# SG2002 register map
Vendor: Sophgo; Series: SG2002; File version: 1.0
SG2002 device
CPU: other r0p0, little endian, no MPU, FPU, VTOR, 7 interrupt priority bits
Registers are 32-bit, read-write, reset 0x0 unless marked. A register's access mark holds for its fields unless they carry their own. Offsets are from the block's base; lines under a group give offsets from that group; [hi:lo] are bit positions; {n}, {i} and the like mark numbered series; 'fields as' and 'values as' point back to an identical list; <NAME> marks a mode.

## Memory map
0x03001000 PINMUX size 0x200 — FMUX
0x03001A00 IOBLK_G10 size 0x100 — PINCTRL of IOBLK_G10

## PINMUX — FMUX
Base 0x03001000
{0x0+4i} PAD[{i}] (i=0..119) group — no desc
  0x00 FUNC_SEL — Function selection
    [3:0] VALUE

## IOBLK_G10 — PINCTRL of IOBLK_G10
Base 0x03001A00
{0x0+4i} PIN[{i}] (i=0..59) group — no desc
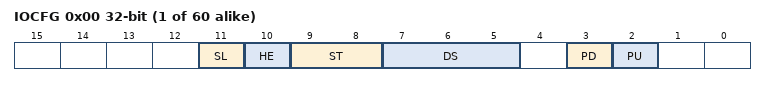
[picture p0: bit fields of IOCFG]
  0x00 IOCFG — IO conf
    [11] SL — Skew control
    [10] HE — Bus holder, some group does not have this
    [9:8] ST — Schmitt trigger enable
    [7:5] DS — Drive strength, some are 3-bit, some are 2-bit
    [3] PD — Pull down enable
    [2] PU — Pull up enable

## Licence text in the file
This file is licensed under the terms of the license listed in the file 'LICENSE' at the root of this repository. The license can also be found at [TODO] All Rights Reserved (c) 2024 Andelf
